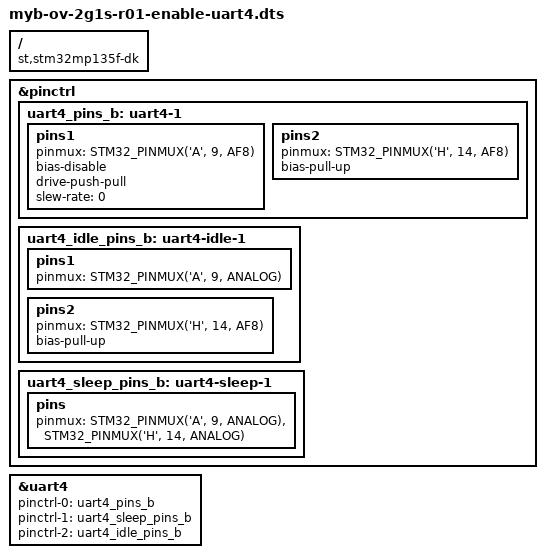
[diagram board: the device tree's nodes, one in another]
/dts-v1/;
/plugin/;

#include <dt-bindings/gpio/gpio.h>
#include <dt-bindings/pinctrl/stm32-pinfunc.h>

/ {
    compatible = "st,stm32mp135f-dk", "st,stm32mp135";

    fragment@0 {
        target = <&pinctrl>;
        __overlay__ {
            uart4_pins_b: uart4-1 {
                pins1 {
                    pinmux = <STM32_PINMUX('A', 9, AF8)>; /* UART4_TX */
                    bias-disable;
                    drive-push-pull;
                    slew-rate = <0>;
                };
                pins2 {
                    pinmux = <STM32_PINMUX('H', 14, AF8)>; /* UART4_RX */
                    bias-pull-up;
                };
            };

            uart4_idle_pins_b: uart4-idle-1 {
                pins1 {
                    pinmux = <STM32_PINMUX('A', 9, ANALOG)>; /* UART4_TX */
                };
                pins2 {
                    pinmux = <STM32_PINMUX('H', 14, AF8)>; /* UART4_RX */
                    bias-pull-up;
                };
            };

            uart4_sleep_pins_b: uart4-sleep-1 {
                pins {
                    pinmux = <STM32_PINMUX('A', 9, ANALOG)>, /* UART4_TX */
                        <STM32_PINMUX('H', 14, ANALOG)>; /* UART4_RX */
                };
            };
        };
    };

    fragment@1 {
        target = <&uart4>;
        __overlay__ {
            pinctrl-names = "default", "sleep", "idle";
            pinctrl-0 = <&uart4_pins_b>;
            pinctrl-1 = <&uart4_sleep_pins_b>;
            pinctrl-2 = <&uart4_idle_pins_b>;
            status = "okay";
        };
    };
};
